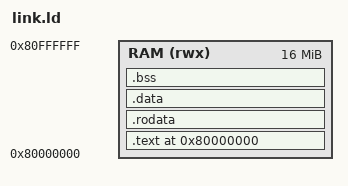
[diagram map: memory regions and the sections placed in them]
/* Linker script for RISC-V test programs */

OUTPUT_ARCH(riscv)
ENTRY(_start)

MEMORY
{
    RAM (rwx) : ORIGIN = 0x80000000, LENGTH = 16M
}

SECTIONS
{
    . = 0x80000000;

    .text : {
        *(.text)
        *(.text.*)
    } > RAM

    .rodata : {
        *(.rodata)
        *(.rodata.*)
    } > RAM

    .data : {
        *(.data)
        *(.data.*)
    } > RAM

    .bss : {
        __bss_start = .;
        *(.bss)
        *(.bss.*)
        *(COMMON)
        __bss_end = .;
    } > RAM

    . = ALIGN(4);
    _end = .;
}
